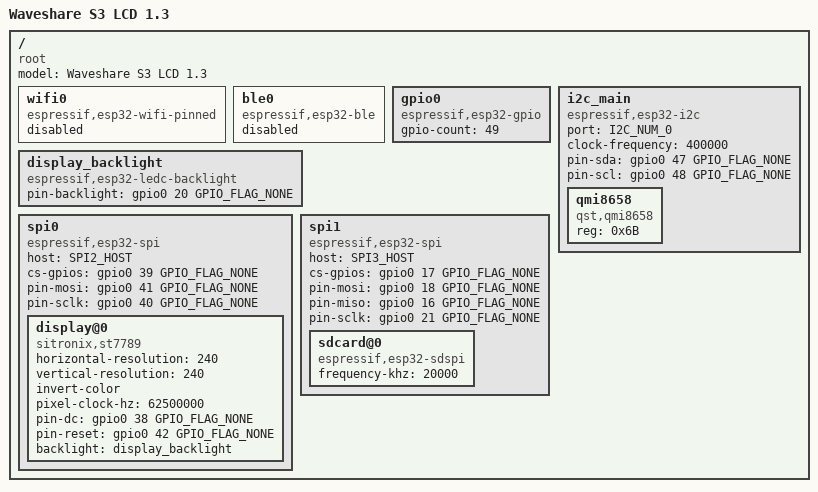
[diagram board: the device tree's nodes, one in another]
/dts-v1/;

#include <tactility/bindings/root.h>
#include <tactility/bindings/esp32_ble.h>
#include <tactility/bindings/esp32_wifi_pinned.h>
#include <tactility/bindings/esp32_gpio.h>
#include <tactility/bindings/esp32_i2c.h>
#include <tactility/bindings/esp32_spi.h>
#include <bindings/qmi8658.h>
#include <tactility/bindings/esp32_sdspi.h>
#include <tactility/bindings/esp32_ledc_backlight.h>
#include <bindings/st7789.h>

// Reference: https://www.waveshare.com/wiki/ESP32-S3-LCD-1.3
/ {
	compatible = "root";
	model = "Waveshare S3 LCD 1.3";

	wifi0 {
		compatible = "espressif,esp32-wifi-pinned";
		status = "disabled";
	};

	ble0 {
		compatible = "espressif,esp32-ble";
		status = "disabled";
	};

	gpio0 {
		compatible = "espressif,esp32-gpio";
		gpio-count = <49>;
	};

	i2c_main {
		compatible = "espressif,esp32-i2c";
		port = <I2C_NUM_0>;
		clock-frequency = <400000>;
		pin-sda = <&gpio0 47 GPIO_FLAG_NONE>;
		pin-scl = <&gpio0 48 GPIO_FLAG_NONE>;

		qmi8658 {
			compatible = "qst,qmi8658";
			reg = <0x6B>;
		};
	};

	display_backlight {
		compatible = "espressif,esp32-ledc-backlight";
		pin-backlight = <&gpio0 20 GPIO_FLAG_NONE>;
	};

	spi0 {
		compatible = "espressif,esp32-spi";
		host = <SPI2_HOST>;
		cs-gpios = <&gpio0 39 GPIO_FLAG_NONE>;
		pin-mosi = <&gpio0 41 GPIO_FLAG_NONE>;
		pin-sclk = <&gpio0 40 GPIO_FLAG_NONE>;

		display@0 {
			compatible = "sitronix,st7789";
			horizontal-resolution = <240>;
			vertical-resolution = <240>;
			invert-color;
			pixel-clock-hz = <62500000>;
			pin-dc = <&gpio0 38 GPIO_FLAG_NONE>;
			pin-reset = <&gpio0 42 GPIO_FLAG_NONE>;
			backlight = <&display_backlight>;
		};
	};

	spi1 {
		compatible = "espressif,esp32-spi";
		host = <SPI3_HOST>;
		cs-gpios = <&gpio0 17 GPIO_FLAG_NONE>;
		pin-mosi = <&gpio0 18 GPIO_FLAG_NONE>;
		pin-miso = <&gpio0 16 GPIO_FLAG_NONE>;
		pin-sclk = <&gpio0 21 GPIO_FLAG_NONE>;
	
		sdcard@0 {
			compatible = "espressif,esp32-sdspi";
			frequency-khz = <20000>;
		};
	};
};
